AUTOSAR XML (schema 00048)
package /ComponentTypes
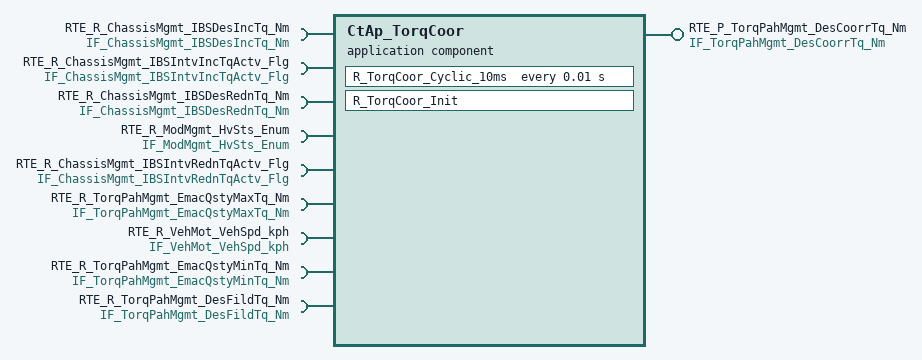
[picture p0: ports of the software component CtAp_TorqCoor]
  application sw component type CtAp_TorqCoor
    provide port RTE_P_TorqPahMgmt_DesCoorrTq_Nm: nonqueued-sender-com-spec{data-element=tec_TorqPahMgmt_DesCoorrTq_Nm, init-value=0}, provided-interface=IF_TorqPahMgmt_DesCoorrTq_Nm
    9 x require port:
      RTE_R_ChassisMgmt_IBSDesIncTq_Nm: nonqueued-receiver-com-spec{data-element=tec_ChassisMgmt_IBSDesIncTq_Nm, filter=data-filter-type=ALWAYS, init-value=0}, required-interface=IF_ChassisMgmt_IBSDesIncTq_Nm
      RTE_R_ChassisMgmt_IBSIntvIncTqActv_Flg: nonqueued-receiver-com-spec{data-element=tec_ChassisMgmt_IBSIntvIncTqActv_Flg, filter=data-filter-type=ALWAYS, init-value=0}, required-interface=IF_ChassisMgmt_IBSIntvIncTqActv_Flg
      RTE_R_ChassisMgmt_IBSDesRednTq_Nm: nonqueued-receiver-com-spec{data-element=tec_ChassisMgmt_IBSDesRednTq_Nm, filter=data-filter-type=ALWAYS, init-value=0}, required-interface=IF_ChassisMgmt_IBSDesRednTq_Nm
      RTE_R_ModMgmt_HvSts_Enum: nonqueued-receiver-com-spec{data-element=tec_ModMgmt_HvSts_Enum, filter=data-filter-type=ALWAYS, init-value=0}, required-interface=IF_ModMgmt_HvSts_Enum
      RTE_R_ChassisMgmt_IBSIntvRednTqActv_Flg: nonqueued-receiver-com-spec{data-element=tec_ChassisMgmt_IBSIntvRednTqActv_Flg, filter=data-filter-type=ALWAYS, init-value=0}, required-interface=IF_ChassisMgmt_IBSIntvRednTqActv_Flg
      RTE_R_TorqPahMgmt_EmacQstyMaxTq_Nm: nonqueued-receiver-com-spec{data-element=tec_TorqPahMgmt_EmacQstyMaxTq_Nm, filter=data-filter-type=ALWAYS, init-value=0}, required-interface=IF_TorqPahMgmt_EmacQstyMaxTq_Nm
      RTE_R_VehMot_VehSpd_kph: nonqueued-receiver-com-spec{data-element=tec_VehMot_VehSpd_kph, filter=data-filter-type=ALWAYS, init-value=0}, required-interface=IF_VehMot_VehSpd_kph
      RTE_R_TorqPahMgmt_EmacQstyMinTq_Nm: nonqueued-receiver-com-spec{data-element=tec_TorqPahMgmt_EmacQstyMinTq_Nm, filter=data-filter-type=ALWAYS, init-value=0}, required-interface=IF_TorqPahMgmt_EmacQstyMinTq_Nm
      RTE_R_TorqPahMgmt_DesFildTq_Nm: nonqueued-receiver-com-spec{data-element=tec_TorqPahMgmt_DesFildTq_Nm, filter=data-filter-type=ALWAYS, init-value=0}, required-interface=IF_TorqPahMgmt_DesFildTq_Nm
    behavior CtAp_TorqCoor_InternalBehavior
      timing event TMT_R_TorqCoor_Cyclic_10ms: start-on-event=R_TorqCoor_Cyclic_10ms, period=0.01
      init event CtAp_TorqCoor_InitEvent: start-on-event=R_TorqCoor_Init
      runnable R_TorqCoor_Cyclic_10ms
        data-receive-point-by-arguments:
          9 x access:
            REC_RTE_R_ChassisMgmt_IBSDesIncTq_Nm_tec_ChassisMgmt_IBSDesIncTq_Nm: accessed-variable=RTE_R_ChassisMgmt_IBSDesIncTq_Nm.tec_ChassisMgmt_IBSDesIncTq_Nm
            REC_RTE_R_ChassisMgmt_IBSDesRednTq_Nm_tec_ChassisMgmt_IBSDesRednTq_Nm: accessed-variable=RTE_R_ChassisMgmt_IBSDesRednTq_Nm.tec_ChassisMgmt_IBSDesRednTq_Nm
            REC_RTE_R_ChassisMgmt_IBSIntvIncTqActv_Flg_tec_ChassisMgmt_IBSIntvIncTqActv_Flg: accessed-variable=RTE_R_ChassisMgmt_IBSIntvIncTqActv_Flg.tec_ChassisMgmt_IBSIntvIncTqActv_Flg
            REC_RTE_R_ChassisMgmt_IBSIntvRednTqActv_Flg_tec_ChassisMgmt_IBSIntvRednTqActv_Flg: accessed-variable=RTE_R_ChassisMgmt_IBSIntvRednTqActv_Flg.tec_ChassisMgmt_IBSIntvRednTqActv_Flg
            REC_RTE_R_ModMgmt_HvSts_Enum_tec_ModMgmt_HvSts_Enum: accessed-variable=RTE_R_ModMgmt_HvSts_Enum.tec_ModMgmt_HvSts_Enum
            REC_RTE_R_TorqPahMgmt_DesFildTq_Nm_tec_TorqPahMgmt_DesFildTq_Nm: accessed-variable=RTE_R_TorqPahMgmt_DesFildTq_Nm.tec_TorqPahMgmt_DesFildTq_Nm
            REC_RTE_R_TorqPahMgmt_EmacQstyMaxTq_Nm_tec_TorqPahMgmt_EmacQstyMaxTq_Nm: accessed-variable=RTE_R_TorqPahMgmt_EmacQstyMaxTq_Nm.tec_TorqPahMgmt_EmacQstyMaxTq_Nm
            REC_RTE_R_TorqPahMgmt_EmacQstyMinTq_Nm_tec_TorqPahMgmt_EmacQstyMinTq_Nm: accessed-variable=RTE_R_TorqPahMgmt_EmacQstyMinTq_Nm.tec_TorqPahMgmt_EmacQstyMinTq_Nm
            REC_RTE_R_VehMot_VehSpd_kph_tec_VehMot_VehSpd_kph: accessed-variable=RTE_R_VehMot_VehSpd_kph.tec_VehMot_VehSpd_kph
        data-send-points:
          access SEND_RTE_P_TorqPahMgmt_DesCoorrTq_Nm_tec_TorqPahMgmt_DesCoorrTq_Nm: accessed-variable=RTE_P_TorqPahMgmt_DesCoorrTq_Nm.tec_TorqPahMgmt_DesCoorrTq_Nm
      runnable R_TorqCoor_Init
  swc implementation CtAp_TorqCoor_Implementation: behavior=CtAp_TorqCoor_InternalBehavior
